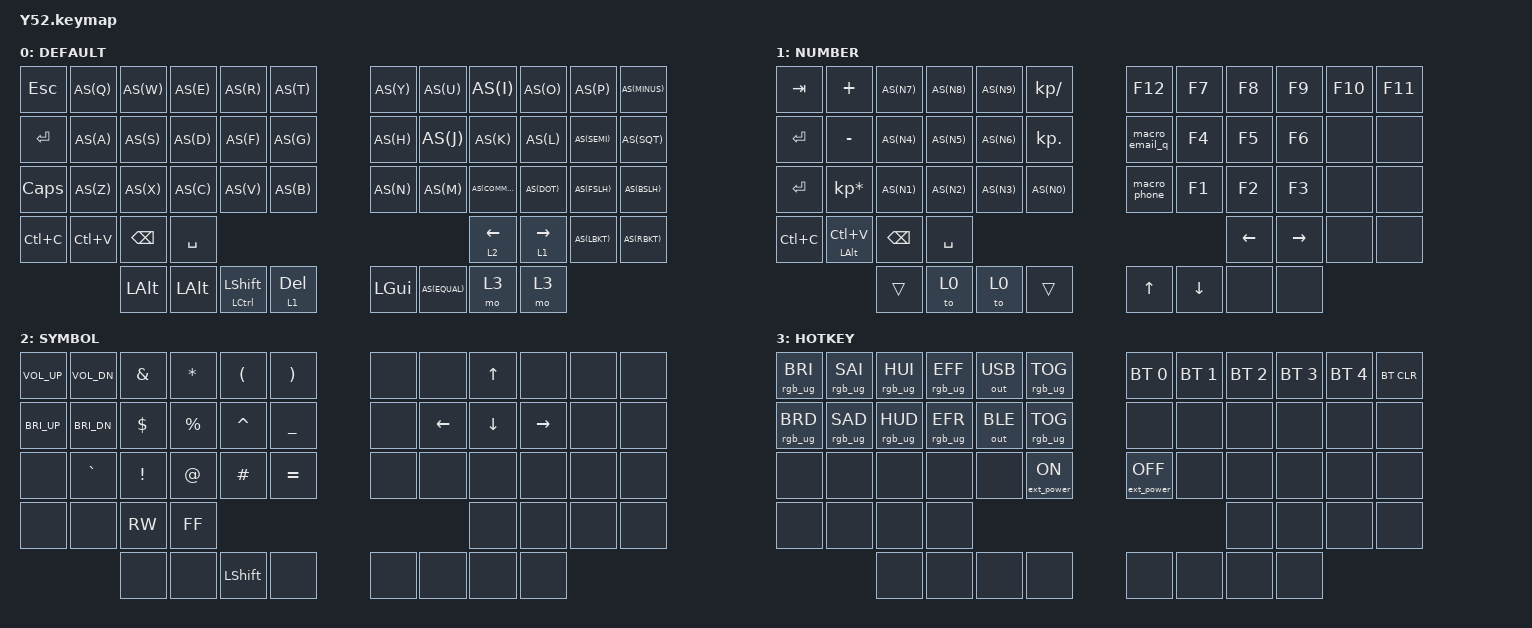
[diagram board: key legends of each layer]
/*
 * Copyright (c) 2020 The ZMK Contributors
 *
 * SPDX-License-Identifier: MIT
 */

#include <behaviors.dtsi>
#include <dt-bindings/zmk/keys.h>
#include <dt-bindings/zmk/bt.h>
#include <dt-bindings/zmk/rgb.h>
#include <dt-bindings/zmk/outputs.h>
#include <dt-bindings/zmk/ext_power.h>



#define DEFAULT 0
#define NUMBER  1
#define SYMBOL  2
#define HOTKEY  3

#define AS(keycode) &as LS(keycode) keycode




/ {
        behaviors {
        td0: tap_dance_0 {
            compatible = "zmk,behavior-tap-dance";
            label = "TAP_DANCE_0";
            #binding-cells = <0>;
            tapping-term-ms = <200>;
            bindings = <&kp ESC>, <&kp TAB>;
        };
    };  

         behaviors {
       as: auto_shift {
        compatible = "zmk,behavior-hold-tap";
        label = "AUTO_SHIFT";
        #binding-cells = <2>;
        tapping-term-ms = <200>;
        quick-tap-ms = <0>;
        flavor = "tap-preferred";
        bindings = <&kp>, <&kp>;
                };             
modcp: mod_copy {
        compatible = "zmk,behavior-mod-morph";
        label = "MOD_COPY";
        #binding-cells = <0>;
        bindings = <&as LS(C) C>, <&kp C>;
        mods = <(LGUI | RGUI)>;
};
        };


    macros {
        macro_phone: macro_phone {
            // 1351
            label = "MACRO_PHONE";
            compatible = "zmk,behavior-macro";
            #binding-cells = <0>;
            bindings
                = < &kp N1 &kp N3 &kp N5  &kp N1>
                ;
        };
        macro_email_q: macro_email_q {
            // 2894512440@qq.com
            label = "MACRO_EMAIL_QQ";
            compatible = "zmk,behavior-macro";
            #binding-cells = <0>;
            bindings 
                = < &kp N2 &kp N8 &kp N9 &kp N4 &kp N5 &kp  N1 &kp N2 &kp N4 &kp N4 &kp N0 
                    &kp AT &kp Q &kp Q &kp DOT  &kp C &kp O &kp M>
                ;
        };
        macro_email_g: macro_email_g {
            // 135115
            compatible = "zmk,behavior-macro";
            label = "MACRO_EMAIL_GMAIL";
            #binding-cells = <0>;
            bindings
                = < &kp N1 &kp N3 &kp N5  &kp N1 &kp N1 &kp N5 > ;
        };
       
    };
    
     combos {
        compatible = "zmk,combos";
        combo_esc {
            timeout-ms = <50>;
            key-positions = <0 1>;
            bindings = <&kp TAB>;
        };
             combo_rgui {
            timeout-ms = <50>;
            key-positions = <2 3>;
            bindings = <&kp CAPS>;
        };
        
         combo_LSHFT {
            timeout-ms = <50>;
            key-positions = <14 15>;
            bindings = <&kp  LSHFT>;
        };
        
            combo_LGUI {
            timeout-ms = <50>;
            key-positions = <26 27>;
            bindings = <&kp LGUI>;
        };
              combo_GUI {
            timeout-ms = <50>;
            key-positions = <28 29>;
            bindings = <&tog 1>;
        };
        
  
   };



    keymap {
       compatible = "zmk,keymap";
       default_layer {
            label = "DEFAULT";
            bindings = <
   &kp ESC AS(Q) AS(W) AS(E) AS(R) AS(T)           AS(Y) AS(U) AS(I)     AS(O)   AS(P)  AS(MINUS) 
   &kp ENTER AS(A) AS(S) AS(D) AS(F) AS(G)     AS(H) AS(J) AS(K)     AS(L)  AS(SEMI)    AS(SQT) 
   &kp CAPS  AS(Z) AS(X) AS(C) AS(V) AS(B)                 AS(N) AS(M) AS(COMMA) AS(DOT) AS(FSLH)   AS(BSLH) 
 &kp LC(C) &kp LC(V) &kp BSPC &kp SPACE     &lt 2 LEFT  &lt 1 RIGHT    AS(LBKT)   AS(RBKT)      
 &kp LALT  &kp LALT &mt LCTRL  LSHFT  &lt 1  DEL     &kp LGUI   AS(EQUAL)   &mo 3   &mo 3    
            >;
        };  


          number_layer {
            label = "NUMBER";
            bindings = <
   &kp TAB  &kp PLUS AS(N7) AS(N8)  AS(N9)   &kp KP_SLASH    &kp F12 &kp F7 &kp F8 &kp F9 &kp F10 &kp F11
    &kp ENTER   &kp MINUS  AS(N4) AS(N5)   AS(N6)  &kp KP_DOT        &macro_email_q    &kp F4 &kp F5 &kp F6    &none &none
   &kp ENTER &kp KP_MULTIPLY  AS(N1) AS(N2) AS(N3) AS(N0)          &macro_phone  &kp F1 &kp F2 &kp F3 &none &none
  &kp LC(C) &mt  LALT LC(V)  &kp BSPC  &kp SPACE                                 &kp LEFT &kp RIGHT &none &none
     &trans    &to 0 &to 0   &trans                                             &kp UP &kp DOWN &none &none
            >;
        };

        symbol_layer {
            label = "SYMBOL";
            bindings = <
 &kp C_VOL_UP  &kp C_VOL_DN  &kp AMPS  &kp STAR &kp LPAR  &kp RPAR       &none &none &kp UP &none &none &none 
&kp C_BRI_UP &kp C_BRI_DN &kp DLLR   &kp PRCNT   &kp CARET &kp UNDER     &none &kp LEFT &kp DOWN &kp RIGHT  &none &none 
 &none  &kp GRAVE &kp EXCL  &kp AT   &kp HASH &kp EQUAL     &none &none &none &none  &none &none
 &none &none &kp C_RW &kp C_FF                                      &none &none &none &none 
 &none &none &kp LSHFT  &none                                   &none &none &none &none                                                                                           
         >;
        };


        hotkey_layer {
            label = "HOTKEY";
            bindings = <
   &rgb_ug RGB_BRI  &rgb_ug RGB_SAI  &rgb_ug RGB_HUI  &rgb_ug RGB_EFF  &out OUT_USB &rgb_ug RGB_TOG            &bt BT_SEL 0 &bt BT_SEL 1 &bt BT_SEL 2 &bt BT_SEL 3 &bt BT_SEL 4 &bt BT_CLR
   &rgb_ug RGB_BRD &rgb_ug RGB_SAD &rgb_ug RGB_HUD &rgb_ug RGB_EFR &out OUT_BLE &rgb_ug RGB_TOG                                &none    &none   &none &none &none   &none 
&none &none &none &none &none &ext_power EP_ON                                            &ext_power EP_OFF &none &none &none &none &none
   &none &none &none &none                                                              &none &none &none &none
   &none &none &none &none                                                              &none &none &none &none                                                     
            >;
        };
   };
};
